# WKUPAON_PRM register map
Vendor: Texas Instruments
Peripheral module from a debugger description file (folder am571x).
Registers are 32-bit, access per field, reset 0x1 unless marked. A register's access mark holds for its fields unless they carry their own. Offsets are as the file gives them; lines under a group give offsets from that group; [hi:lo] are bit positions; {n}, {i} and the like mark numbered series; 'fields as' and 'values as' point back to an identical list; <NAME> marks a mode.

## WKUPAON_PRM
0x24 RM_WKUPAON_L4_WKUP_CONTEXT — This register contains dedicated L4_WKUP context statuses. [warm reset insensitive]
  [0] LOSTCONTEXT_DFF rw — Specify if DFF-based context has been lost due to a previous power transition or other reset source. (set upon assertion of WKUPAON_RST signal)
    0=MAINTAINED (Context has been maintained); 1=LOST (Context has been lost)
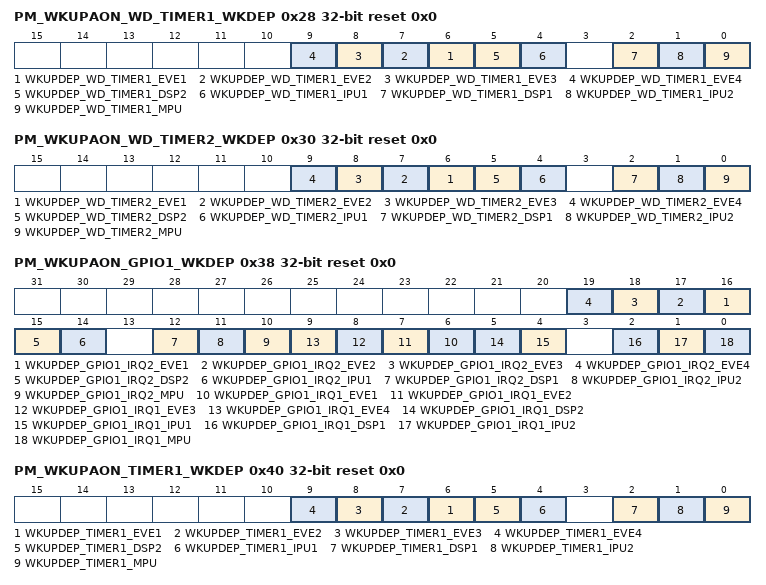
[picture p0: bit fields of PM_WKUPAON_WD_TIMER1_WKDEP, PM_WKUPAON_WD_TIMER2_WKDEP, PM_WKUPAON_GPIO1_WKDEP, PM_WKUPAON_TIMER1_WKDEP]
0x28 PM_WKUPAON_WD_TIMER1_WKDEP reset 0x0 — This register controls wakeup dependency based on WD_TIMER1 service requests.
  [all] fields
    0=DISABLED (Dependency is disabled); 1=ENABLED (Dependency is enabled)
  [n+5] WKUPDEP_WD_TIMER1_EVE{n} rw (n=1..4) — Wakeup dependency from TIMER module (SWakeup IRQ signal) towards EVE{n} + L3_MAIN1 + L4PER1 + L4PER2 + L4PER3 domains
  [5] WKUPDEP_WD_TIMER1_DSP2 rw — Wakeup dependency from TIMER module (SWakeup IRQ signal) towards DSP2 + L3_MAIN1 + L4PER1 + L4PER2 + L4PER3 domains
  [4] WKUPDEP_WD_TIMER1_IPU1 rw — Wakeup dependency from TIMER module (SWakeup IRQ signal) towards IPU1 + L3_MAIN1 + L4PER1 + L4PER2 + L4PER3 domains
  [2] WKUPDEP_WD_TIMER1_DSP1 rw — Wakeup dependency from TIMER module (SWakeup IRQ signal) towards DSP + L3MAIN1 + L4PER1 + L4PER2 + L4PER3 domains
  [1] WKUPDEP_WD_TIMER1_IPU2 rw — Wakeup dependency from TIMER module (SWakeup IRQ signal) towards IPU2 + L3_MAIN1 + L4PER1 + L4PER2 + L4PER3 domains
  [0] WKUPDEP_WD_TIMER1_MPU rw — Wakeup dependency from WDT1 module (SWakeup signal) towards MPU + L3MAIN1 + L4CFG domains
0x2C RM_WKUPAON_WD_TIMER1_CONTEXT — This register contains dedicated WD_TIMER1 context statuses. [warm reset insensitive]
  [0] LOSTCONTEXT_DFF rw — Specify if DFF-based context has been lost due to a previous power transition or other reset source. (set upon assertion of WKUPAON_PWRON_RST signal)
    values as RM_WKUPAON_L4_WKUP_CONTEXT.LOSTCONTEXT_DFF
0x30 PM_WKUPAON_WD_TIMER2_WKDEP reset 0x0 — This register controls wakeup dependency based on WD_TIMER2 service requests.
  [all] fields
    values as the fields of PM_WKUPAON_WD_TIMER1_WKDEP
  [n+5] WKUPDEP_WD_TIMER2_EVE{n} rw (n=1..4) — Wakeup dependency from TIMER module (SWakeup IRQ signal) towards EVE{n} + L3_MAIN1 + L4PER1 + L4PER2 + L4PER3 domains
  [5] WKUPDEP_WD_TIMER2_DSP2 rw — Wakeup dependency from TIMER module (SWakeup IRQ signal) towards DSP2 + L3_MAIN1 + L4PER1 + L4PER2 + L4PER3 domains
  [4] WKUPDEP_WD_TIMER2_IPU1 rw — Wakeup dependency from TIMER module (SWakeup IRQ signal) towards IPU1 + L3_MAIN1 + L4PER1 + L4PER2 + L4PER3 domains
  [2] WKUPDEP_WD_TIMER2_DSP1 rw — Wakeup dependency from TIMER module (SWakeup IRQ signal) towards DSP + L3MAIN1 + L4PER1 + L4PER2 + L4PER3 domains
  [1] WKUPDEP_WD_TIMER2_IPU2 rw — Wakeup dependency from TIMER module (SWakeup IRQ signal) towards IPU2 + L3_MAIN1 + L4PER1 + L4PER2 + L4PER3 domains
  [0] WKUPDEP_WD_TIMER2_MPU rw — Wakeup dependency from WDT2 module (SWakeup signal) towards MPU + L3MAIN1 + L4CFG domains
0x34 RM_WKUPAON_WD_TIMER2_CONTEXT — This register contains dedicated WD_TIMER2 context statuses. [warm reset insensitive]
  fields as RM_WKUPAON_L4_WKUP_CONTEXT
0x38 PM_WKUPAON_GPIO1_WKDEP reset 0x0 — This register controls wakeup dependency based on GPIO1 service requests.
  [all] fields
    values as the fields of PM_WKUPAON_WD_TIMER1_WKDEP
  [n+15] WKUPDEP_GPIO1_IRQ2_EVE{n} rw (n=1..4) — Wakeup dependency from GPIO1 module (SWakeup signal) towards EVE{n} + L3_MAIN1 + L4PER1 + L4PER2 + L4PER3 domains
  [15] WKUPDEP_GPIO1_IRQ2_DSP2 rw — Wakeup dependency from GPIO1 module (SWakeup signal) towards DSP2 + L3_MAIN1 + L4PER1 + L4PER2 + L4PER3 domains
  [14] WKUPDEP_GPIO1_IRQ2_IPU1 rw — Wakeup dependency from GPIO1 module (SWakeup signal) towards IPU1 + L3_MAIN1 + L4PER1 + L4PER2 + L4PER3 domains
  [12] WKUPDEP_GPIO1_IRQ2_DSP1 rw — Wakeup dependency from GPIO1 module (SWakeup signal) towards DSP + L3MAIN1 + L4PER1 + L4PER2 + L4PER3 domains
  [11] WKUPDEP_GPIO1_IRQ2_IPU2 rw — Wakeup dependency from GPIO1 module (SWakeup signal) towards IPU2 + L3_MAIN1 + L4PER1 + L4PER2 + L4PER3 domains
  [10] WKUPDEP_GPIO1_IRQ2_MPU rw — Wakeup dependency from GPIO1 module (SWakeup signal) towards MPU + L3_MAIN1 + L4PER1 + L4PER2 + L4PER3 domains
  [n+5] WKUPDEP_GPIO1_IRQ1_EVE{n} rw (n=1..4) — Wakeup dependency from GPIO1 module (SWakeup signal) towards EVE{n} + L3_MAIN1 + L4PER1 + L4PER2 + L4PER3 domains
  [5] WKUPDEP_GPIO1_IRQ1_DSP2 rw — Wakeup dependency from GPIO1 module (SWakeup signal) towards DSP2 + L3_MAIN1 + L4PER1 + L4PER2 + L4PER3 domains
  [4] WKUPDEP_GPIO1_IRQ1_IPU1 rw — Wakeup dependency from GPIO1 module (SWakeup signal) towards IPU1 + L3_MAIN1 + L4PER1 + L4PER2 + L4PER3 domains
  [2] WKUPDEP_GPIO1_IRQ1_DSP1 rw — Wakeup dependency from GPIO1 module (SWakeup signal) towards DSP + L3MAIN1 + L4PER1 + L4PER2 + L4PER3 domains
  [1] WKUPDEP_GPIO1_IRQ1_IPU2 rw — Wakeup dependency from GPIO1 module (SWakeup signal) towards IPU2 + L3_MAIN1 + L4PER1 + L4PER2 + L4PER3 domains
  [0] WKUPDEP_GPIO1_IRQ1_MPU rw — Wakeup dependency from GPIO1 module (SWakeup signal for POROCPSINTERRUPT1 ) towards MPU + L3_MAIN1 + L4PER1 + L4PER2 + L4PER3 domains
0x3C RM_WKUPAON_GPIO1_CONTEXT — This register contains dedicated GPIO1 context statuses. [warm reset insensitive]
  fields as RM_WKUPAON_L4_WKUP_CONTEXT
0x40 PM_WKUPAON_TIMER1_WKDEP reset 0x0 — This register controls wakeup dependency based on TIMER1 service requests.
  [all] fields
    values as the fields of PM_WKUPAON_WD_TIMER1_WKDEP
  [n+5] WKUPDEP_TIMER1_EVE{n} rw (n=1..4) — Wakeup dependency from TIMER1 module (SWakeup IRQ signal) towards EVE{n} + L3_MAIN1 + L4PER1 + L4PER2 + L4PER3 domains
  [5] WKUPDEP_TIMER1_DSP2 rw — Wakeup dependency from TIMER1 module (SWakeup IRQ signal) towards DSP2 + L3_MAIN1 + L4PER1 + L4PER2 + L4PER3 domains
  [4] WKUPDEP_TIMER1_IPU1 rw — Wakeup dependency from TIMER1 module (SWakeup IRQ signal) towards IPU1 + L3_MAIN1 + L4PER1 + L4PER2 + L4PER3 domains
  [2] WKUPDEP_TIMER1_DSP1 rw — Wakeup dependency from TIMER1 module (SWakeup IRQ signal) towards DSP + L3MAIN1 + L4PER1 + L4PER2 + L4PER3 domains
  [1] WKUPDEP_TIMER1_IPU2 rw — Wakeup dependency from TIMER4 module (SWakeup IRQ signal) towards IPU2 + L3_MAIN1 + L4PER1 + L4PER2 + L4PER3 domains
  [0] WKUPDEP_TIMER1_MPU rw — Wakeup dependency from TIMER1 module (SWakeup IRQ signal) towards MPU + L3_MAIN1 + L4PER1 + L4PER2 + L4PER3 domains
0x44 RM_WKUPAON_TIMER1_CONTEXT — This register contains dedicated TIMER1 context statuses. [warm reset insensitive]
  fields as RM_WKUPAON_L4_WKUP_CONTEXT
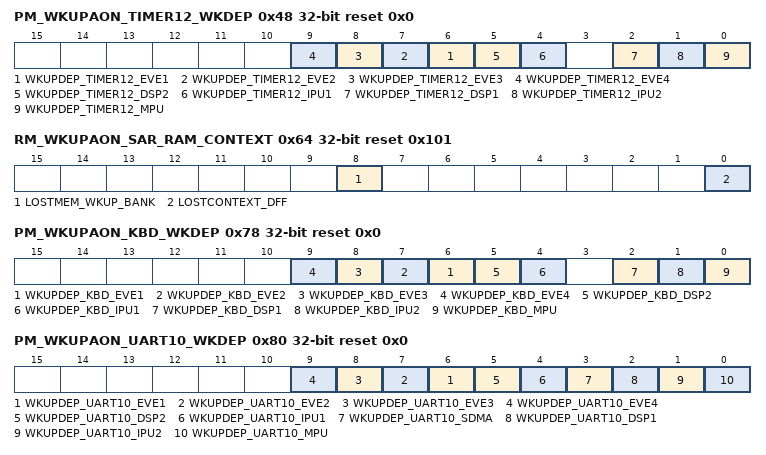
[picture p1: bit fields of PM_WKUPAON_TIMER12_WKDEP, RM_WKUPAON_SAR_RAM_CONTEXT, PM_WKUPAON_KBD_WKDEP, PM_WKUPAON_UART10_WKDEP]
0x48 PM_WKUPAON_TIMER12_WKDEP reset 0x0 — This register controls wakeup dependency based on TIMER12 service requests.
  [all] fields
    values as the fields of PM_WKUPAON_WD_TIMER1_WKDEP
  [n+5] WKUPDEP_TIMER12_EVE{n} rw (n=1..4) — Wakeup dependency from TIMER12 module (SWakeup IRQ signal) towards EVE{n} + L3_MAIN1 + L4PER1 + L4PER2 + L4PER3 domains
  [5] WKUPDEP_TIMER12_DSP2 rw — Wakeup dependency from TIMER12 module (SWakeup IRQ signal) towards DSP2 + L3_MAIN1 + L4PER1 + L4PER2 + L4PER3 domains
  [4] WKUPDEP_TIMER12_IPU1 rw — Wakeup dependency from TIMER12 module (SWakeup IRQ signal) towards IPU1 + L3_MAIN1 + L4PER1 + L4PER2 + L4PER3 domains
  [2] WKUPDEP_TIMER12_DSP1 rw — Wakeup dependency from TIMER12 module (SWakeup IRQ signal) towards DSP + L3MAIN1 + L4PER1 + L4PER2 + L4PER3 domains
  [1] WKUPDEP_TIMER12_IPU2 rw — Wakeup dependency from TIMER12 module (SWakeup IRQ signal) towards IPU2 + L3_MAIN1 + L4PER1 + L4PER2 + L4PER3 domains
  [0] WKUPDEP_TIMER12_MPU rw — Wakeup dependency from TIMER12 module (SWakeup IRQ signal) towards MPU + L3_MAIN1 + L4PER1 + L4PER2 + L4PER3 domains
0x4C RM_WKUPAON_TIMER12_CONTEXT — This register contains dedicated TIMER12 context statuses. [warm reset insensitive]
  fields as RM_WKUPAON_L4_WKUP_CONTEXT
0x54 RM_WKUPAON_COUNTER_32K_CONTEXT — This register contains dedicated COUNTER_32K context statuses. This bit-field is only sensitive to the external power-on reset (SYS_PWRON_RST reset line)
  [0] LOSTCONTEXT_DFF rw — Specify if DFF-based context has been lost due to a previous power transition or other reset source. (set upon assertion of WKUPAON_SYS_PWRON_RST signal)
    values as RM_WKUPAON_L4_WKUP_CONTEXT.LOSTCONTEXT_DFF
0x64 RM_WKUPAON_SAR_RAM_CONTEXT reset 0x101 — This register contains dedicated SAR_RAM context statuses. [warm reset insensitive]
  [8] LOSTMEM_WKUP_BANK rw — Specify if memory-based context in WKUP_BANK memory bank has been lost due to a previous global cold reset.
    values as RM_WKUPAON_L4_WKUP_CONTEXT.LOSTCONTEXT_DFF
  [0] LOSTCONTEXT_DFF rw — Specify if DFF-based context has been lost due to a previous power transition or other reset source. (set upon assertion of WKUPAON_RST signal)
    values as RM_WKUPAON_L4_WKUP_CONTEXT.LOSTCONTEXT_DFF
0x78 PM_WKUPAON_KBD_WKDEP reset 0x0 — This register controls wakeup dependency based on KBD service requests.
  [all] fields
    values as the fields of PM_WKUPAON_WD_TIMER1_WKDEP
  [n+5] WKUPDEP_KBD_EVE{n} rw (n=1..4) — Wakeup dependency from KBD module (SWakeup IRQ signal) towards EVE{n} + L3_MAIN1 + L4PER1 + L4PER2 + L4PER3 domains
  [5] WKUPDEP_KBD_DSP2 rw — Wakeup dependency from KBD module (SWakeup IRQ signal) towards DSP2 + L3_MAIN1 + L4PER1 + L4PER2 + L4PER3 domains
  [4] WKUPDEP_KBD_IPU1 rw — Wakeup dependency from KBD module (SWakeup IRQ signal) towards IPU1 + L3_MAIN1 + L4PER1 + L4PER2 + L4PER3 domains
  [2] WKUPDEP_KBD_DSP1 rw — Wakeup dependency from KBD module (SWakeup IRQ signal) towards DSP + L3MAIN1 + L4PER1 + L4PER2 + L4PER3 domains
  [1] WKUPDEP_KBD_IPU2 rw — Wakeup dependency from KBD module (SWakeup IRQ signal) towards IPU2 + L3_MAIN1 + L4PER1 + L4PER2 + L4PER3 domains
  [0] WKUPDEP_KBD_MPU rw — Wakeup dependency from KBD module (SWakeup IRQ signal) towards MPU + L3_MAIN1 + L4PER1 + L4PER2 + L4PER3 domains
0x7C RM_WKUPAON_KBD_CONTEXT — This register contains dedicated KBD context statuses. [warm reset insensitive]
  fields as RM_WKUPAON_L4_WKUP_CONTEXT
0x80 PM_WKUPAON_UART10_WKDEP reset 0x0 — This register controls wakeup dependency based on UART10 service requests.
  [all] fields
    values as the fields of PM_WKUPAON_WD_TIMER1_WKDEP
  [n+5] WKUPDEP_UART10_EVE{n} rw (n=1..4) — Wakeup dependency from UART10 module (SWakeup signal) towards EVE{n} + L3_MAIN1 + L4PER1 + L4PER2 + L4PER3 domains
  [5] WKUPDEP_UART10_DSP2 rw — Wakeup dependency from UART10 module (SWakeup signal) towards DSP2 + L3_MAIN1 + L4PER1 + L4PER2 + L4PER3 domains
  [4] WKUPDEP_UART10_IPU1 rw — Wakeup dependency from UART10 module (SWakeup signal) towards IPU1 + L3_MAIN1 + L4PER1 + L4PER2 + L4PER3 domains
  [3] WKUPDEP_UART10_SDMA rw — Wakeup dependency from UART10 module (SWakeup signal) towards SDMA + L3MAIN1 + L4PER1 + L4PER2 + L4PER3 domains
  [2] WKUPDEP_UART10_DSP1 rw — Wakeup dependency from UART10 module (SWakeup signal) towards DSP + L3MAIN1 + L4PER1 + L4PER2 + L4PER3 domains
  [1] WKUPDEP_UART10_IPU2 rw — Wakeup dependency from UART10 module (SWakeup signal) towards IPU2 + L3_MAIN1 + L4PER1 + L4PER2 + L4PER3 domains
  [0] WKUPDEP_UART10_MPU rw — Wakeup dependency from UART10 module (SWakeup signal) towards MPU + L3_MAIN1 + L4PER1 + L4PER2 + L4PER3 domains
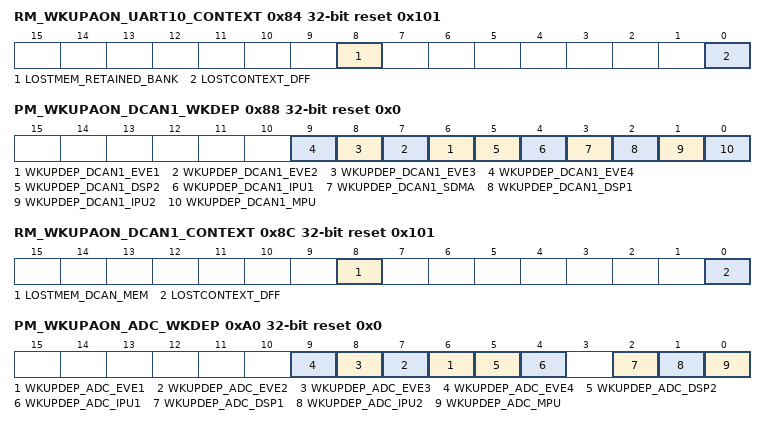
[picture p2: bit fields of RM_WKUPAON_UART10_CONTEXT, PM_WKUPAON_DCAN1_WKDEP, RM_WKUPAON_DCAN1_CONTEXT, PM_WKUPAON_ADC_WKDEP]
0x84 RM_WKUPAON_UART10_CONTEXT reset 0x101 — This register contains dedicated UART10 context statuses. [warm reset insensitive]
  [8] LOSTMEM_RETAINED_BANK rw — Specify if memory-based context in UART memory bank has been lost due to a previous power transition or other reset source.
    values as RM_WKUPAON_L4_WKUP_CONTEXT.LOSTCONTEXT_DFF
  [0] LOSTCONTEXT_DFF rw — Specify if DFF-based context has been lost due to a previous power transition or other reset source. (set upon assertion of WKUPAON_RST signal)
    values as RM_WKUPAON_L4_WKUP_CONTEXT.LOSTCONTEXT_DFF
0x88 PM_WKUPAON_DCAN1_WKDEP reset 0x0 — This register controls wakeup dependency based on DCAN1 service requests.
  [all] fields
    values as the fields of PM_WKUPAON_WD_TIMER1_WKDEP
  [n+5] WKUPDEP_DCAN1_EVE{n} rw (n=1..4) — Wakeup dependency from DCAN1 module (SWakeup signal) towards EVE{n} + L3_MAIN1 + L4PER1 + L4PER2 + L4PER3 domains
  [5] WKUPDEP_DCAN1_DSP2 rw — Wakeup dependency from DCAN1 module (SWakeup signal) towards DSP2 + L3_MAIN1 + L4PER1 + L4PER2 + L4PER3 domains
  [4] WKUPDEP_DCAN1_IPU1 rw — Wakeup dependency from DCAN1 module (SWakeup signal) towards IPU1 + L3_MAIN1 + L4PER1 + L4PER2 + L4PER3 domains
  [3] WKUPDEP_DCAN1_SDMA rw — Wakeup dependency from DCAN1 module (SWakeup signal) towards SDMA + L3MAIN1 + L4PER1 + L4PER2 + L4PER3 domains
  [2] WKUPDEP_DCAN1_DSP1 rw — Wakeup dependency from DCAN1 module (SWakeup signal) towards DSP + L3MAIN1 + L4PER1 + L4PER2 + L4PER3 domains
  [1] WKUPDEP_DCAN1_IPU2 rw — Wakeup dependency from DCAN1 module (SWakeup signal) towards IPU2 + L3_MAIN1 + L4PER1 + L4PER2 + L4PER3 domains
  [0] WKUPDEP_DCAN1_MPU rw — Wakeup dependency from DCAN1 module (SWakeup signal) towards MPU + L3_MAIN1 + L4PER1 + L4PER2 + L4PER3 domains
0x8C RM_WKUPAON_DCAN1_CONTEXT reset 0x101 — This register contains dedicated DCAN1 context statuses. [warm reset insensitive]
  [8] LOSTMEM_DCAN_MEM rw — Specify if memory-based context in DCAN memory bank has been lost due to a previous power transition or other reset source.
    values as RM_WKUPAON_L4_WKUP_CONTEXT.LOSTCONTEXT_DFF
  [0] LOSTCONTEXT_DFF rw — Specify if DFF-based context has been lost due to a previous power transition or other reset source. (set upon assertion of WKUPAON_RST signal)
    values as RM_WKUPAON_L4_WKUP_CONTEXT.LOSTCONTEXT_DFF
0xA0 PM_WKUPAON_ADC_WKDEP reset 0x0 — This register controls wakeup dependency based on ADC service requests.
  [all] fields
    values as the fields of PM_WKUPAON_WD_TIMER1_WKDEP
  [n+5] WKUPDEP_ADC_EVE{n} rw (n=1..4) — Wakeup dependency from ADC module (SWakeup signal) towards EVE{n} + L3_MAIN1 + L4PER1 + L4PER2 + L4PER3 domains
  [5] WKUPDEP_ADC_DSP2 rw — Wakeup dependency from ADC module (SWakeup signal) towards DSP2 + L3_MAIN1 + L4PER1 + L4PER2 + L4PER3 domains
  [4] WKUPDEP_ADC_IPU1 rw — Wakeup dependency from ADC module (SWakeup signal) towards IPU1 + L3_MAIN1 + L4PER1 + L4PER2 + L4PER3 domains
  [2] WKUPDEP_ADC_DSP1 rw — Wakeup dependency from ADC module (SWakeup signal) towards DSP + L3MAIN1 + L4PER1 + L4PER2 + L4PER3 domains
  [1] WKUPDEP_ADC_IPU2 rw — Wakeup dependency from ADC module (SWakeup signal) towards IPU2 + L3_MAIN1 + L4PER1 + L4PER2 + L4PER3 domains
  [0] WKUPDEP_ADC_MPU rw — Wakeup dependency from ADC module (SWakeup signal) towards MPU + L3_MAIN1 + L4PER1 + L4PER2 + L4PER3 domains
0xA4 RM_WKUPAON_ADC_CONTEXT — This register contains dedicated ADC context statuses. [warm reset insensitive]
  [0] LOSTCONTEXT_DFF rw — Specify if DFF-based context has been lost due to a previous power transition or other reset source. (set upon assertion of CAM_RST signal)
    values as RM_WKUPAON_L4_WKUP_CONTEXT.LOSTCONTEXT_DFF
{0xAC+8i} RM_WKUPAON_SPARE_SAFETY{i}_CONTEXT (i=1..4) — This register contains dedicated SPARE_SAFETY{i} context statuses. [warm reset insensitive]
  fields as RM_WKUPAON_L4_WKUP_CONTEXT
0xD4 RM_WKUPAON_SPARE_UNKNOWN2_CONTEXT — This register contains dedicated SPARE_UNKNOWN2 context statuses. [warm reset insensitive]
  fields as RM_WKUPAON_L4_WKUP_CONTEXT
0xDC RM_WKUPAON_SPARE_UNKNOWN3_CONTEXT — This register contains dedicated SPARE_UNKNOWN3 context statuses. [warm reset insensitive]
  fields as RM_WKUPAON_L4_WKUP_CONTEXT
